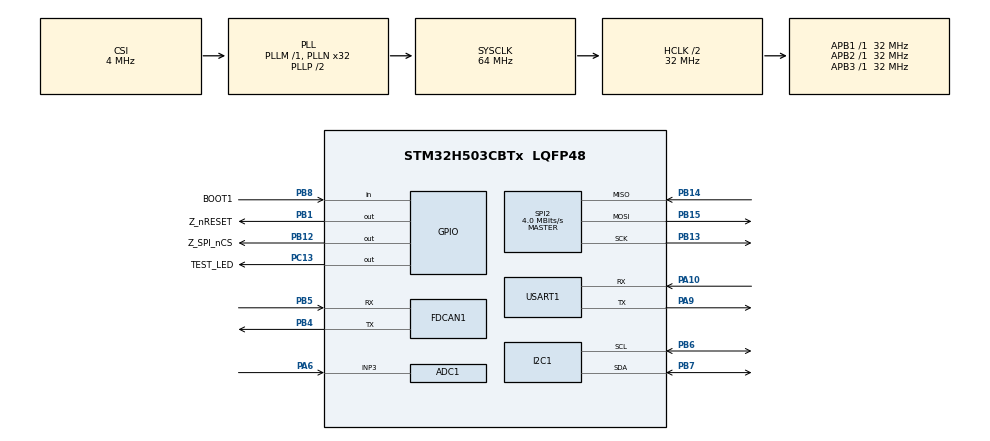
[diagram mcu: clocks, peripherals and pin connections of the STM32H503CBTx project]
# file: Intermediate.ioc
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ADC1.Channel-3\#ChannelRegularConversion=ADC_CHANNEL_3
ADC1.MonitoredBy-3\#ChannelRegularConversion=__NULL
ADC1.NbrOfConversionFlag=1
ADC1.OffsetNumber-3\#ChannelRegularConversion=ADC_OFFSET_NONE
ADC1.Rank-3\#ChannelRegularConversion=1
ADC1.SamplingTime-3\#ChannelRegularConversion=ADC_SAMPLETIME_2CYCLES_5
ADC1.master=1
BOOTPATH.BootPathName=LEGACY
BOOTPATH.UserSelectedBootPath=LEGACY
CORTEX_M33_NS.Number-Cortex_Memory_Protection_Unit_Region0_OTP_RO_AREAS_Settings=MPU_REGION_NUMBER0
CORTEX_M33_NS.default_mode_Activation=1
FDCAN1.CalculateBaudRateNominal=500000
FDCAN1.CalculateTimeBitNominal=2000
FDCAN1.CalculateTimeQuantumNominal=250.0
FDCAN1.ExtFiltersNbr=1
FDCAN1.Mode=FDCAN_MODE_INTERNAL_LOOPBACK
FDCAN1.NominalPrescaler=16
FDCAN1.NominalTimeSeg1=5
FDCAN1.NominalTimeSeg2=2
I2C1.I2C_Fall_Time=15
I2C1.I2C_Rise_Time=150
I2C1.Timing=0x00C07DB5
Mcu.Family=STM32H5
Mcu.Name=STM32H503CBTx
Mcu.Package=LQFP48
NVIC.PriorityGroup=NVIC_PRIORITYGROUP_4
PA10.Mode=Asynchronous
PA10.Signal=USART1_RX
PA11.Signal=USB_DM
PA12.Signal=USB_DP
PA13(JTMS/SWDIO).Mode=Serial_Wire
PA13(JTMS/SWDIO).Signal=DEBUG_JTMS-SWDIO
PA14(JTCK/SWCLK).Mode=Serial_Wire
PA14(JTCK/SWCLK).Signal=DEBUG_JTCK-SWCLK
PA6.Signal=ADCx_INP3
PA9.Mode=Asynchronous
PA9.Signal=USART1_TX
PB1.GPIO_Label=Z_nRESET
PB1.PinState=GPIO_PIN_SET
PB1.Signal=GPIO_Output
PB12.GPIO_Label=Z_SPI_nCS
PB12.PinState=GPIO_PIN_SET
PB12.Signal=GPIO_Output
PB13.Mode=Full_Duplex_Master
PB13.Signal=SPI2_SCK
PB14.Mode=Full_Duplex_Master
PB14.Signal=SPI2_MISO
PB15.Mode=Full_Duplex_Master
PB15.Signal=SPI2_MOSI
PB4(NJTRST).Mode=FDCAN_Activate
PB4(NJTRST).Signal=FDCAN1_TX
PB5.Mode=FDCAN_Activate
PB5.Signal=FDCAN1_RX
PB6.GPIO_FM6=__NULL
PB6.GPIO_Mode=GPIO_MODE_AF_OD
PB6.GPIO_Pu=GPIO_NOPULL
PB6.GPIO_Speed=GPIO_SPEED_FREQ_LOW
PB6.Mode=I2C
PB6.Signal=I2C1_SCL
PB7.GPIO_FM7=__NULL
PB7.GPIO_Mode=GPIO_MODE_AF_OD
PB7.GPIO_Pu=GPIO_NOPULL
PB7.GPIO_Speed=GPIO_SPEED_FREQ_LOW
PB7.Mode=I2C
PB7.Signal=I2C1_SDA
PB8.GPIO_Label=BOOT1
PB8.Signal=GPIO_Input
PC13.GPIO_Label=TEST_LED
PC13.Signal=GPIO_Output
PC14-OSC32_IN(OSC32_IN).Mode=LSE-External-Oscillator
PC14-OSC32_IN(OSC32_IN).Signal=RCC_OSC32_IN
PC15-OSC32_OUT(OSC32_OUT).Mode=LSE-External-Oscillator
PC15-OSC32_OUT(OSC32_OUT).Signal=RCC_OSC32_OUT
PH0-OSC_IN(PH0).Mode=HSE-External-Oscillator
PH0-OSC_IN(PH0).Signal=RCC_OSC_IN
PH1-OSC_OUT(PH1).Mode=HSE-External-Oscillator
PH1-OSC_OUT(PH1).Signal=RCC_OSC_OUT
ProjectManager.HeapSize=0x200
ProjectManager.StackSize=0x400
ProjectManager.TargetToolchain=STM32CubeIDE
RCC.ADCFreq_Value=32000000
RCC.AHBCLKDivider=RCC_SYSCLK_DIV2
RCC.AHBFreq_Value=32000000
RCC.APB1Freq_Value=32000000
RCC.APB1TimFreq_Value=32000000
RCC.APB2Freq_Value=32000000
RCC.APB2TimFreq_Value=32000000
RCC.APB3Freq_Value=32000000
RCC.CSI_VALUE=4000000
RCC.CortexFreq_Value=32000000
RCC.EPOD_VALUE=4000000
RCC.FDCANClockSelection=RCC_FDCANCLKSOURCE_PLL1Q
RCC.HCLKFreq_Value=32000000
RCC.HSE_VALUE=8000000
RCC.HSI48_VALUE=48000000
RCC.HSI_VALUE=64000000
RCC.LSIRC_VALUE=32000
RCC.PLLFRACN=0
RCC.PLLN=32
RCC.SYSCLKFreq_VALUE=64000000
RCC.SYSCLKSource=RCC_SYSCLKSOURCE_PLLCLK
RCC.USBFreq_Value=48000000
RCC.VCOOutputFreq_Value=128000000
SH.ADCx_INP3.0=ADC1_INP3,IN3-Single-Ended
SPI2.BaudRatePrescaler=SPI_BAUDRATEPRESCALER_16
SPI2.CalculateBaudRate=4.0 MBits/s
SPI2.DataSize=SPI_DATASIZE_8BIT
SPI2.Direction=SPI_DIRECTION_2LINES
SPI2.Mode=SPI_MODE_MASTER
SPI2.NSSPMode=SPI_NSS_PULSE_DISABLE
SPI2.VirtualType=VM_MASTER
USART1.VirtualMode-Asynchronous=VM_ASYNC
VP_BOOTPATH_VS_BOOTPATH.Mode=BP_Activate
VP_CORTEX_M33_NS_VS_Ext.Mode=External_Mode
VP_ICACHE_VS_ICACHE.Mode=DirectMappedCache
VP_MEMORYMAP_VS_MEMORYMAP.Mode=CurAppReg
VP_PWR_VS_LPOM.Mode=PowerOptimisation
VP_PWR_VS_SECSignals.Mode=Security/Privilege
board=custom

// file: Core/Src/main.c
/* USER CODE BEGIN Header */
/**
  ******************************************************************************
  * @file           : main.c
  * @brief          : Main program body
  ******************************************************************************
  * @attention
  *
  * Copyright (c) 2026 STMicroelectronics.
  * All rights reserved.
  *
  * This software is licensed under terms that can be found in the LICENSE file
  * in the root directory of this software component.
  * If no LICENSE file comes with this software, it is provided AS-IS.
  *
  ******************************************************************************
  */
/* USER CODE END Header */
#include "main.h"

/* USER CODE BEGIN Includes */
#include "peripheral_training.h"
/* USER CODE END Includes */

ADC_HandleTypeDef hadc1;

FDCAN_HandleTypeDef hfdcan1;

I2C_HandleTypeDef hi2c1;

SPI_HandleTypeDef hspi2;

UART_HandleTypeDef huart1;

void SystemClock_Config(void);
static void MPU_Config(void);
static void MX_GPIO_Init(void);
static void MX_I2C1_Init(void);
static void MX_ICACHE_Init(void);
static void MX_SPI2_Init(void);
static void MX_USART1_UART_Init(void);
static void MX_ADC1_Init(void);
static void MX_FDCAN1_Init(void);

int main(void)
{

  /* MCU Configuration--------------------------------------------------------*/

  /* MPU Configuration--------------------------------------------------------*/
  MPU_Config();

  /* Reset of all peripherals, Initializes the Flash interface and the Systick. */
  HAL_Init();

  /* Configure the system clock */
  SystemClock_Config();

  /* Initialize all configured peripherals */
  MX_GPIO_Init();
  MX_I2C1_Init();
  MX_ICACHE_Init();
  MX_SPI2_Init();
  MX_USART1_UART_Init();
  MX_ADC1_Init();
  MX_FDCAN1_Init();
  /* USER CODE BEGIN 2 */
  Peripheral_Training_Init();
  /* USER CODE END 2 */

  /* Infinite loop */
  while (1)
  {

  }
}

void SystemClock_Config(void)
{
  RCC_OscInitTypeDef RCC_OscInitStruct = {0};
  RCC_ClkInitTypeDef RCC_ClkInitStruct = {0};

  /** Configure the main internal regulator output voltage
  */
  __HAL_PWR_VOLTAGESCALING_CONFIG(PWR_REGULATOR_VOLTAGE_SCALE3);

  while(!__HAL_PWR_GET_FLAG(PWR_FLAG_VOSRDY)) {}

  /** Initializes the RCC Oscillators according to the specified parameters
  * in the RCC_OscInitTypeDef structure.
  */
  RCC_OscInitStruct.OscillatorType = RCC_OSCILLATORTYPE_CSI;
  RCC_OscInitStruct.CSIState = RCC_CSI_ON;
  RCC_OscInitStruct.CSICalibrationValue = RCC_CSICALIBRATION_DEFAULT;
  RCC_OscInitStruct.PLL.PLLState = RCC_PLL_ON;
  RCC_OscInitStruct.PLL.PLLSource = RCC_PLL1_SOURCE_CSI;
  RCC_OscInitStruct.PLL.PLLM = 1;
  RCC_OscInitStruct.PLL.PLLN = 32;
  RCC_OscInitStruct.PLL.PLLP = 2;
  RCC_OscInitStruct.PLL.PLLQ = 2;
  RCC_OscInitStruct.PLL.PLLR = 2;
  RCC_OscInitStruct.PLL.PLLRGE = RCC_PLL1_VCIRANGE_2;
  RCC_OscInitStruct.PLL.PLLVCOSEL = RCC_PLL1_VCORANGE_WIDE;
  RCC_OscInitStruct.PLL.PLLFRACN = 0;
  if (HAL_RCC_OscConfig(&RCC_OscInitStruct) != HAL_OK)
  {
    Error_Handler();
  }

  /** Initializes the CPU, AHB and APB buses clocks
  */
  RCC_ClkInitStruct.ClockType = RCC_CLOCKTYPE_HCLK|RCC_CLOCKTYPE_SYSCLK
                              |RCC_CLOCKTYPE_PCLK1|RCC_CLOCKTYPE_PCLK2
                              |RCC_CLOCKTYPE_PCLK3;
  RCC_ClkInitStruct.SYSCLKSource = RCC_SYSCLKSOURCE_PLLCLK;
  RCC_ClkInitStruct.AHBCLKDivider = RCC_SYSCLK_DIV2;
  RCC_ClkInitStruct.APB1CLKDivider = RCC_HCLK_DIV1;
  RCC_ClkInitStruct.APB2CLKDivider = RCC_HCLK_DIV1;
  RCC_ClkInitStruct.APB3CLKDivider = RCC_HCLK_DIV1;

  if (HAL_RCC_ClockConfig(&RCC_ClkInitStruct, FLASH_LATENCY_3) != HAL_OK)
  {
    Error_Handler();
  }

   /* Select SysTick source clock */
  HAL_SYSTICK_CLKSourceConfig(SYSTICK_CLKSOURCE_HCLK);

   /* Re-Initialize Tick with new clock source */
  if (HAL_InitTick(TICK_INT_PRIORITY) != HAL_OK)
  {
    Error_Handler();
  }

  /** Configure the programming delay
  */
  __HAL_FLASH_SET_PROGRAM_DELAY(FLASH_PROGRAMMING_DELAY_1);
}

static void MX_ADC1_Init(void)
{

  ADC_ChannelConfTypeDef sConfig = {0};

  /** Common config
  */
  hadc1.Instance = ADC1;
  hadc1.Init.ClockPrescaler = ADC_CLOCK_ASYNC_DIV2;
  hadc1.Init.Resolution = ADC_RESOLUTION_12B;
  hadc1.Init.DataAlign = ADC_DATAALIGN_RIGHT;
  hadc1.Init.ScanConvMode = ADC_SCAN_DISABLE;
  hadc1.Init.EOCSelection = ADC_EOC_SINGLE_CONV;
  hadc1.Init.LowPowerAutoWait = DISABLE;
  hadc1.Init.ContinuousConvMode = DISABLE;
  hadc1.Init.NbrOfConversion = 1;
  hadc1.Init.DiscontinuousConvMode = DISABLE;
  hadc1.Init.ExternalTrigConv = ADC_SOFTWARE_START;
  hadc1.Init.ExternalTrigConvEdge = ADC_EXTERNALTRIGCONVEDGE_NONE;
  hadc1.Init.DMAContinuousRequests = DISABLE;
  hadc1.Init.SamplingMode = ADC_SAMPLING_MODE_NORMAL;
  hadc1.Init.Overrun = ADC_OVR_DATA_PRESERVED;
  hadc1.Init.OversamplingMode = DISABLE;
  if (HAL_ADC_Init(&hadc1) != HAL_OK)
  {
    Error_Handler();
  }

  /** Configure Regular Channel
  */
  sConfig.Channel = ADC_CHANNEL_3;
  sConfig.Rank = ADC_REGULAR_RANK_1;
  sConfig.SamplingTime = ADC_SAMPLETIME_2CYCLES_5;
  sConfig.SingleDiff = ADC_SINGLE_ENDED;
  sConfig.OffsetNumber = ADC_OFFSET_NONE;
  sConfig.Offset = 0;
  if (HAL_ADC_ConfigChannel(&hadc1, &sConfig) != HAL_OK)
  {
    Error_Handler();
  }

}

static void MX_FDCAN1_Init(void)
{

  hfdcan1.Instance = FDCAN1;
  hfdcan1.Init.ClockDivider = FDCAN_CLOCK_DIV1;
  hfdcan1.Init.FrameFormat = FDCAN_FRAME_CLASSIC;
  hfdcan1.Init.Mode = FDCAN_MODE_INTERNAL_LOOPBACK;
  hfdcan1.Init.AutoRetransmission = DISABLE;
  hfdcan1.Init.TransmitPause = DISABLE;
  hfdcan1.Init.ProtocolException = DISABLE;
  hfdcan1.Init.NominalPrescaler = 16;
  hfdcan1.Init.NominalSyncJumpWidth = 1;
  hfdcan1.Init.NominalTimeSeg1 = 5;
  hfdcan1.Init.NominalTimeSeg2 = 2;
  hfdcan1.Init.DataPrescaler = 1;
  hfdcan1.Init.DataSyncJumpWidth = 1;
  hfdcan1.Init.DataTimeSeg1 = 1;
  hfdcan1.Init.DataTimeSeg2 = 1;
  hfdcan1.Init.StdFiltersNbr = 0;
  hfdcan1.Init.ExtFiltersNbr = 1;
  hfdcan1.Init.TxFifoQueueMode = FDCAN_TX_FIFO_OPERATION;
  if (HAL_FDCAN_Init(&hfdcan1) != HAL_OK)
  {
    Error_Handler();
  }

}

static void MX_I2C1_Init(void)
{

  hi2c1.Instance = I2C1;
  hi2c1.Init.Timing = 0x00C07DB5;
  hi2c1.Init.OwnAddress1 = 0;
  hi2c1.Init.AddressingMode = I2C_ADDRESSINGMODE_7BIT;
  hi2c1.Init.DualAddressMode = I2C_DUALADDRESS_DISABLE;
  hi2c1.Init.OwnAddress2 = 0;
  hi2c1.Init.OwnAddress2Masks = I2C_OA2_NOMASK;
  hi2c1.Init.GeneralCallMode = I2C_GENERALCALL_DISABLE;
  hi2c1.Init.NoStretchMode = I2C_NOSTRETCH_DISABLE;
  if (HAL_I2C_Init(&hi2c1) != HAL_OK)
  {
    Error_Handler();
  }

  /** Configure Analogue filter
  */
  if (HAL_I2CEx_ConfigAnalogFilter(&hi2c1, I2C_ANALOGFILTER_ENABLE) != HAL_OK)
  {
    Error_Handler();
  }

  /** Configure Digital filter
  */
  if (HAL_I2CEx_ConfigDigitalFilter(&hi2c1, 0) != HAL_OK)
  {
    Error_Handler();
  }

}

static void MX_ICACHE_Init(void)
{

  /** Enable instruction cache in 1-way (direct mapped cache)
  */
  if (HAL_ICACHE_ConfigAssociativityMode(ICACHE_1WAY) != HAL_OK)
  {
    Error_Handler();
  }
  if (HAL_ICACHE_Enable() != HAL_OK)
  {
    Error_Handler();
  }

}

static void MX_SPI2_Init(void)
{

  /* SPI2 parameter configuration*/
  hspi2.Instance = SPI2;
  hspi2.Init.Mode = SPI_MODE_MASTER;
  hspi2.Init.Direction = SPI_DIRECTION_2LINES;
  hspi2.Init.DataSize = SPI_DATASIZE_8BIT;
  hspi2.Init.CLKPolarity = SPI_POLARITY_LOW;
  hspi2.Init.CLKPhase = SPI_PHASE_1EDGE;
  hspi2.Init.NSS = SPI_NSS_SOFT;
  hspi2.Init.BaudRatePrescaler = SPI_BAUDRATEPRESCALER_16;
  hspi2.Init.FirstBit = SPI_FIRSTBIT_MSB;
  hspi2.Init.TIMode = SPI_TIMODE_DISABLE;
  hspi2.Init.CRCCalculation = SPI_CRCCALCULATION_DISABLE;
  hspi2.Init.CRCPolynomial = 0x7;
  hspi2.Init.NSSPMode = SPI_NSS_PULSE_DISABLE;
  hspi2.Init.NSSPolarity = SPI_NSS_POLARITY_LOW;
  hspi2.Init.FifoThreshold = SPI_FIFO_THRESHOLD_01DATA;
  hspi2.Init.MasterSSIdleness = SPI_MASTER_SS_IDLENESS_00CYCLE;
  hspi2.Init.MasterInterDataIdleness = SPI_MASTER_INTERDATA_IDLENESS_00CYCLE;
  hspi2.Init.MasterReceiverAutoSusp = SPI_MASTER_RX_AUTOSUSP_DISABLE;
  hspi2.Init.MasterKeepIOState = SPI_MASTER_KEEP_IO_STATE_DISABLE;
  hspi2.Init.IOSwap = SPI_IO_SWAP_DISABLE;
  hspi2.Init.ReadyMasterManagement = SPI_RDY_MASTER_MANAGEMENT_INTERNALLY;
  hspi2.Init.ReadyPolarity = SPI_RDY_POLARITY_HIGH;
  if (HAL_SPI_Init(&hspi2) != HAL_OK)
  {
    Error_Handler();
  }

}

static void MX_USART1_UART_Init(void)
{

  huart1.Instance = USART1;
  huart1.Init.BaudRate = 115200;
  huart1.Init.WordLength = UART_WORDLENGTH_8B;
  huart1.Init.StopBits = UART_STOPBITS_1;
  huart1.Init.Parity = UART_PARITY_NONE;
  huart1.Init.Mode = UART_MODE_TX_RX;
  huart1.Init.HwFlowCtl = UART_HWCONTROL_NONE;
  huart1.Init.OverSampling = UART_OVERSAMPLING_16;
  huart1.Init.OneBitSampling = UART_ONE_BIT_SAMPLE_DISABLE;
  huart1.Init.ClockPrescaler = UART_PRESCALER_DIV1;
  huart1.AdvancedInit.AdvFeatureInit = UART_ADVFEATURE_NO_INIT;
  if (HAL_UART_Init(&huart1) != HAL_OK)
  {
    Error_Handler();
  }
  if (HAL_UARTEx_SetTxFifoThreshold(&huart1, UART_TXFIFO_THRESHOLD_1_8) != HAL_OK)
  {
    Error_Handler();
  }
  if (HAL_UARTEx_SetRxFifoThreshold(&huart1, UART_RXFIFO_THRESHOLD_1_8) != HAL_OK)
  {
    Error_Handler();
  }
  if (HAL_UARTEx_DisableFifoMode(&huart1) != HAL_OK)
  {
    Error_Handler();
  }

}

static void MX_GPIO_Init(void)
{
  GPIO_InitTypeDef GPIO_InitStruct = {0};

  /* GPIO Ports Clock Enable */
  __HAL_RCC_GPIOC_CLK_ENABLE();
  __HAL_RCC_GPIOH_CLK_ENABLE();
  __HAL_RCC_GPIOA_CLK_ENABLE();
  __HAL_RCC_GPIOB_CLK_ENABLE();

  /*Configure GPIO pin Output Level */
  HAL_GPIO_WritePin(TEST_LED_GPIO_Port, TEST_LED_Pin, GPIO_PIN_RESET);

  /*Configure GPIO pin Output Level */
  HAL_GPIO_WritePin(GPIOB, Z_nRESET_Pin|Z_SPI_nCS_Pin, GPIO_PIN_SET);

  /*Configure GPIO pin : TEST_LED_Pin */
  GPIO_InitStruct.Pin = TEST_LED_Pin;
  GPIO_InitStruct.Mode = GPIO_MODE_OUTPUT_PP;
  GPIO_InitStruct.Pull = GPIO_NOPULL;
  GPIO_InitStruct.Speed = GPIO_SPEED_FREQ_LOW;
  HAL_GPIO_Init(TEST_LED_GPIO_Port, &GPIO_InitStruct);

  /*Configure GPIO pins : Z_nRESET_Pin Z_SPI_nCS_Pin */
  GPIO_InitStruct.Pin = Z_nRESET_Pin|Z_SPI_nCS_Pin;
  GPIO_InitStruct.Mode = GPIO_MODE_OUTPUT_PP;
  GPIO_InitStruct.Pull = GPIO_NOPULL;
  GPIO_InitStruct.Speed = GPIO_SPEED_FREQ_LOW;
  HAL_GPIO_Init(GPIOB, &GPIO_InitStruct);

  /*Configure GPIO pins : PA11 PA12 */
  GPIO_InitStruct.Pin = GPIO_PIN_11|GPIO_PIN_12;
  GPIO_InitStruct.Mode = GPIO_MODE_AF_PP;
  GPIO_InitStruct.Pull = GPIO_NOPULL;
  GPIO_InitStruct.Speed = GPIO_SPEED_FREQ_LOW;
  GPIO_InitStruct.Alternate = GPIO_AF10_USB;
  HAL_GPIO_Init(GPIOA, &GPIO_InitStruct);

  /*Configure GPIO pin : PA13 */
  GPIO_InitStruct.Pin = GPIO_PIN_13;
  GPIO_InitStruct.Mode = GPIO_MODE_AF_PP;
  GPIO_InitStruct.Pull = GPIO_PULLUP;
  GPIO_InitStruct.Speed = GPIO_SPEED_FREQ_LOW;
  GPIO_InitStruct.Alternate = GPIO_AF0_TRACE;
  HAL_GPIO_Init(GPIOA, &GPIO_InitStruct);

  /*Configure GPIO pin : BOOT1_Pin */
  GPIO_InitStruct.Pin = BOOT1_Pin;
  GPIO_InitStruct.Mode = GPIO_MODE_INPUT;
  GPIO_InitStruct.Pull = GPIO_NOPULL;
  HAL_GPIO_Init(BOOT1_GPIO_Port, &GPIO_InitStruct);

}

 /* MPU Configuration */

void MPU_Config(void)
{
  MPU_Region_InitTypeDef MPU_InitStruct = {0};
  MPU_Attributes_InitTypeDef MPU_AttributesInit = {0};

  /* Disables the MPU */
  HAL_MPU_Disable();

  /** Initializes and configures the Region 0 and the memory to be protected
  */
  MPU_InitStruct.Enable = MPU_REGION_ENABLE;
  MPU_InitStruct.Number = MPU_REGION_NUMBER0;
  MPU_InitStruct.BaseAddress = 0x08FFF000;
  MPU_InitStruct.LimitAddress = 0x08FFFFFF;
  MPU_InitStruct.AttributesIndex = MPU_ATTRIBUTES_NUMBER0;
  MPU_InitStruct.AccessPermission = MPU_REGION_ALL_RO;
  MPU_InitStruct.DisableExec = MPU_INSTRUCTION_ACCESS_DISABLE;
  MPU_InitStruct.IsShareable = MPU_ACCESS_NOT_SHAREABLE;

  HAL_MPU_ConfigRegion(&MPU_InitStruct);

  /** Initializes and configures the Attribute 0 and the memory to be protected
  */
  MPU_AttributesInit.Number = MPU_ATTRIBUTES_NUMBER0;
  MPU_AttributesInit.Attributes = INNER_OUTER(MPU_NOT_CACHEABLE);

  HAL_MPU_ConfigMemoryAttributes(&MPU_AttributesInit);
  /* Enables the MPU */
  HAL_MPU_Enable(MPU_PRIVILEGED_DEFAULT);

}

void Error_Handler(void)
{
  __disable_irq();
  while (1)
  {
  }
}
